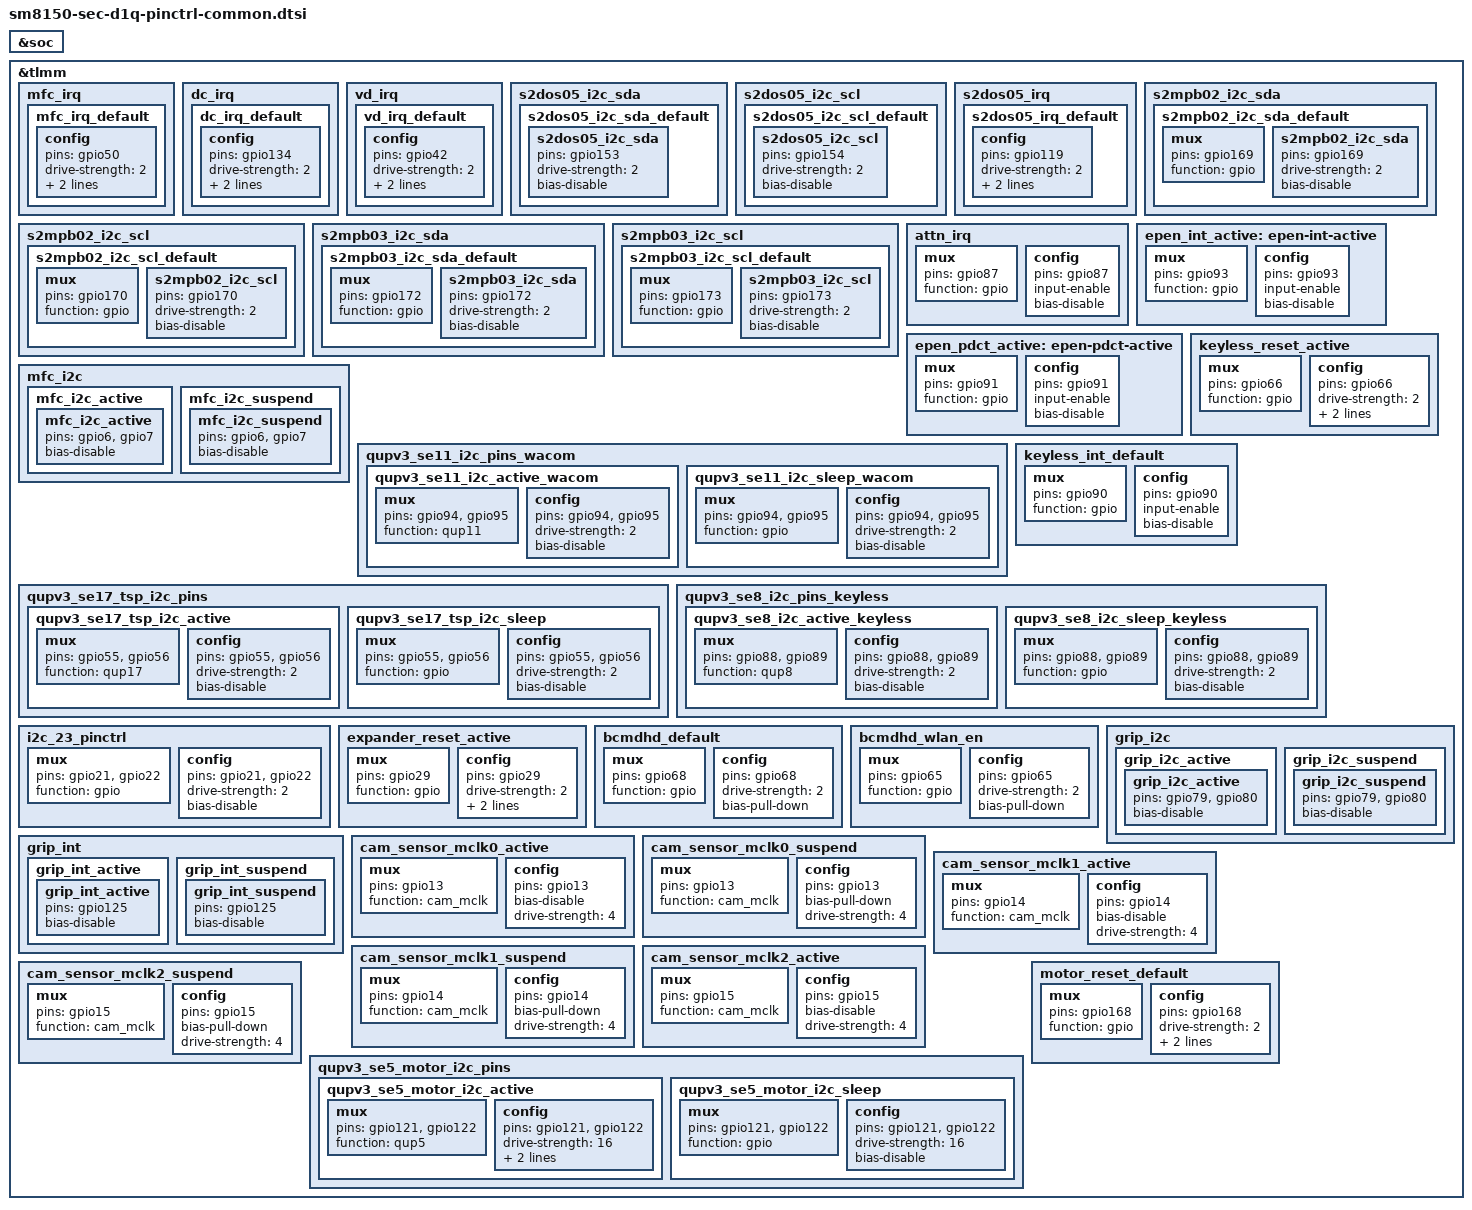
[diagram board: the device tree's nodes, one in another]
/* Copyright (c) 2016-2018, The Linux Foundation. All rights reserved.
 *
 * This program is free software; you can redistribute it and/or modify
 * it under the terms of the GNU General Public License version 2 and
 * only version 2 as published by the Free Software Foundation.
 *
 * This program is distributed in the hope that it will be useful,
 * but WITHOUT ANY WARRANTY; without even the implied warranty of
 * MERCHANTABILITY or FITNESS FOR A PARTICULAR PURPOSE.  See the
 * GNU General Public License for more details.
 */

#include "sm8150-sec-davinciq-audio-pinctrl.dtsi"

&soc {
};

&tlmm {
	mfc_irq {
		mfc_irq_default: mfc_irq_default {
			config {
				pins = "gpio50";
				drive-strength = <2>;
				bias-disable;
				input-enable;
			};
		};
	};

	dc_irq {
		dc_irq_default: dc_irq_default {
			config {
				pins = "gpio134";
				drive-strength = <2>;
				bias-disable;
				input-enable;
			};
		};
	};

	vd_irq {
		vd_irq_default: vd_irq_default {
			config {
				pins = "gpio42";
				drive-strength = <2>;
				bias-pull-up;
				input-enable;
			};
		};
	};

	s2dos05_i2c_sda {
		s2dos05_i2c_sda_default: s2dos05_i2c_sda_default {
			s2dos05_i2c_sda {
				pins = "gpio153";
				drive-strength = <2>;
				bias-disable;
			};
		};
	};
	s2dos05_i2c_scl {
		s2dos05_i2c_scl_default: s2dos05_i2c_scl_default {
			s2dos05_i2c_scl {
				pins = "gpio154";
				drive-strength = <2>;
				bias-disable;
			};
		};
	};
	s2dos05_irq {
		s2dos05_irq_default: s2dos05_irq_default {
			config {
				pins = "gpio119";
				drive-strength = <2>;
				bias-disable;
				input-enable;
			};
		};
	};

	s2mpb02_i2c_sda {
		s2mpb02_i2c_sda_default: s2mpb02_i2c_sda_default {
			mux {
				pins = "gpio169";
				function = "gpio";
			};
			s2mpb02_i2c_sda {
				pins = "gpio169";
				drive-strength = <2>;
				bias-disable;
			};
		};
	};
	s2mpb02_i2c_scl {
		s2mpb02_i2c_scl_default: s2mpb02_i2c_scl_default {
			mux {
				pins = "gpio170";
				function = "gpio";
			};
			s2mpb02_i2c_scl {
				pins = "gpio170";
				drive-strength = <2>;
				bias-disable;
			};
		};
	};

	s2mpb03_i2c_sda {
		s2mpb03_i2c_sda_default: s2mpb03_i2c_sda_default {
			mux {
				pins = "gpio172";
				function = "gpio";
			};
			s2mpb03_i2c_sda {
				pins = "gpio172";
				drive-strength = <2>;
				bias-disable;
			};
		};
	};
	s2mpb03_i2c_scl {
		s2mpb03_i2c_scl_default: s2mpb03_i2c_scl_default {
			mux {
				pins = "gpio173";
				function = "gpio";
			};
			s2mpb03_i2c_scl {
				pins = "gpio173";
				drive-strength = <2>;
				bias-disable;
			};
		};
	};

	attn_irq: attn_irq {
		mux {
			pins = "gpio87";
			function = "gpio";
		};
		config {
			pins = "gpio87";
			input-enable;
			bias-disable;
		};
	};

	epen_int_active: epen-int-active {
		mux {
			pins = "gpio93";
			function = "gpio";
		};
		config {
			pins = "gpio93";
			input-enable;
			bias-disable;
		};
	};

	epen_pdct_active: epen-pdct-active {
		mux {
			pins = "gpio91";
			function = "gpio";
		};
		config {
			pins = "gpio91";
			input-enable;
			bias-disable;
		};
	};

	mfc_i2c {
		mfc_i2c_active: mfc_i2c_active {
			mfc_i2c_active {
				pins = "gpio6", "gpio7";
				bias-disable;
			};
		};
		mfc_i2c_suspend: mfc_i2c_suspend {
			mfc_i2c_suspend {
				pins = "gpio6", "gpio7";
				bias-disable;
			};
		};
	};

	qupv3_se11_i2c_pins_wacom: qupv3_se11_i2c_pins_wacom {
		qupv3_se11_i2c_active_wacom: qupv3_se11_i2c_active_wacom {
			mux {
				pins = "gpio94", "gpio95";
				function = "qup11";
			};

			config {
				pins = "gpio94", "gpio95";
				drive-strength = <2>;
				bias-disable;
			};
		};

		qupv3_se11_i2c_sleep_wacom: qupv3_se11_i2c_sleep_wacom {
			mux {
				pins = "gpio94", "gpio95";
				function = "gpio";
			};

			config {
				pins = "gpio94", "gpio95";
				drive-strength = <2>;
				bias-disable;
			};
		};
	};

#if 0
	muic_i2c {
		muic_i2c_active: muic_i2c_active {
			muic_i2c {
				pins = "gpio25", "gpio26";
				drive-strength = <2>;
				bias-disable;
			};
		};
		muic_i2c_suspend: muic_i2c_suspend {
			muic_i2c {
				pins = "gpio25", "gpio26";
				drive-strength = <2>;
				bias-disable;
			};
		};
	};
#endif
	/* SE 17 pin mappings */
	qupv3_se17_tsp_i2c_pins: qupv3_se17_tsp_i2c_pins {
		qupv3_se17_tsp_i2c_active: qupv3_se17_tsp_i2c_active {
			mux {
				pins = "gpio55", "gpio56";
				function = "qup17";
			};

			config {
				pins = "gpio55", "gpio56";
				drive-strength = <2>;
				bias-disable;
			};
		};

		qupv3_se17_tsp_i2c_sleep: qupv3_se17_tsp_i2c_sleep {
			mux {
				pins = "gpio55", "gpio56";
				function = "gpio";
			};

			config {
				pins = "gpio55", "gpio56";
				drive-strength = <2>;
				bias-disable;
			};
		};
	};

	keyless_reset_active: keyless_reset_active {
		mux {
			pins = "gpio66";
			function = "gpio";
		};
		config {
			pins = "gpio66";
			drive-strength = <2>;   /* 16 mA */
			bias-disable;
			output-low;
		};
	};

	keyless_int_default: keyless_int_default {
		mux {
			pins = "gpio90";
			function = "gpio";
		};
		config {
			pins = "gpio90";
			input-enable;
			bias-disable;
		};
	};

	qupv3_se8_i2c_pins_keyless: qupv3_se8_i2c_pins_keyless {
		qupv3_se8_i2c_active_keyless: qupv3_se8_i2c_active_keyless {
			mux {
				pins = "gpio88", "gpio89";
				function = "qup8";
			};

			config {
				pins = "gpio88", "gpio89";
				drive-strength = <2>;
				bias-disable;
			};
		};

		qupv3_se8_i2c_sleep_keyless: qupv3_se8_i2c_sleep_keyless {
			mux {
				pins = "gpio88", "gpio89";
				function = "gpio";
			};

			config {
				pins = "gpio88", "gpio89";
				drive-strength = <2>;
				bias-disable;
			};
		};
	};

	i2c_23_pinctrl: i2c_23_pinctrl {
		mux {
			pins = "gpio21",	/* EXPANDER_I2C_SDA_1P8 */
			       "gpio22";	/* EXPANDER_I2C_SCL_1P8 */
			function = "gpio";
		};
		config {
			pins = "gpio21",	/* EXPANDER_I2C_SDA_1P8 */
			       "gpio22";	/* EXPANDER_I2C_SCL_1P8 */
			drive-strength = <2>;
			bias-disable;
		};
	};

	expander_reset_active: expander_reset_active {
		mux {
			pins = "gpio29";
			function = "gpio";
		};
		config {
			pins = "gpio29";
			drive-strength = <2>;   /* 16 mA */
			bias-disable;
			output-high;
		};
	};

	bcmdhd_default: bcmdhd_default {
		mux {
			pins = "gpio68";
			function = "gpio";
		};
		config {
			pins = "gpio68";
			drive-strength = <2>;   /* 2 mA */
			bias-pull-down;         /* PULL DOWN */
		};
	};

	bcmdhd_wlan_en: bcmdhd_wlan_en {
		mux {
			pins = "gpio65";
			function = "gpio";
		};
		config {
			pins = "gpio65";
			drive-strength = <2>;   /* 2 mA */
			bias-pull-down;         /* PULL DOWN */
		};
	};

        grip_i2c {
		grip_i2c_active: grip_i2c_active {
			grip_i2c_active {
				pins = "gpio79", "gpio80";
				bias-disable;
			};
		};
		grip_i2c_suspend: grip_i2c_suspend {
			grip_i2c_suspend {
				pins = "gpio79", "gpio80";
				bias-disable;
			};
		};
	};

	grip_int {
		grip_int_active: grip_int_active {
			grip_int_active {
				pins = "gpio125";
				bias-disable;
			};
		};
		grip_int_suspend: grip_int_suspend {
			grip_int_suspend {
				pins = "gpio125";
				bias-disable;
			};
		};
	};

	cam_sensor_mclk0_active: cam_sensor_mclk0_active {
		/* MCLK0 */
		mux {
			pins = "gpio13";
			function = "cam_mclk";
		};
		config {
			pins = "gpio13";
			bias-disable; /* No PULL */
			drive-strength = <4>; /* 4 MA */
		};
	};

	cam_sensor_mclk0_suspend: cam_sensor_mclk0_suspend {
		/* MCLK0 */
		mux {
			pins = "gpio13";
			function = "cam_mclk";
		};
		config {
			pins = "gpio13";
			bias-pull-down; /* PULL DOWN */
			drive-strength = <4>; /* 4 MA */
		};
	};

	cam_sensor_mclk1_active: cam_sensor_mclk1_active {
		/* MCLK1 */
		mux {
			pins = "gpio14";
			function = "cam_mclk";
		};
		config {
			pins = "gpio14";
			bias-disable; /* No PULL */
			drive-strength = <4>; /* 4 MA */
		};
	};

	cam_sensor_mclk1_suspend: cam_sensor_mclk1_suspend {
		/* MCLK1 */
		mux {
			pins = "gpio14";
			function = "cam_mclk";
		};
		config {
			pins = "gpio14";
			bias-pull-down; /* PULL DOWN */
			drive-strength = <4>; /* 4 MA */
		};
	};

	cam_sensor_mclk2_active: cam_sensor_mclk2_active {
		/* MCLK2 */
		mux {
			pins = "gpio15";
			function = "cam_mclk";
		};

		config {
			pins = "gpio15";
			bias-disable; /* No PULL */
			drive-strength = <4>; /* 4 MA */
		};
	};

	cam_sensor_mclk2_suspend: cam_sensor_mclk2_suspend {
		/* MCLK2 */
		mux {
			pins = "gpio15";
			function = "cam_mclk";
		};

		config {
			pins = "gpio15";
			bias-pull-down; /* PULL DOWN */
			drive-strength = <4>; /* 4 MA */
		};
	};

	/* VIB MOTOR IC */
	/delete-node/ qupv3_se5_i2c_pins;

	qupv3_se5_motor_i2c_pins: qupv3_se5_motor_i2c_pins {
		qupv3_se5_motor_i2c_active: qupv3_se5_motor_i2c_active {
			mux {
				pins = "gpio121", "gpio122";
				function = "qup5";
			};

			config {
				pins = "gpio121", "gpio122";
				drive-strength = <16>;
				output-high;
				bias-disable; /* No PULL */
			};
		};

		qupv3_se5_motor_i2c_sleep: qupv3_se5_motor_i2c_sleep {
			mux {
				pins = "gpio121", "gpio122";
				function = "gpio";
			};

			config {
				pins = "gpio121", "gpio122";
				drive-strength = <16>;
				bias-disable; /* No PULL */
			};
		};
	};

	motor_reset_default: motor_reset_default {
		mux {
			pins = "gpio168";
			function = "gpio";
		};
		config {
			pins = "gpio168";
			drive-strength = <2>;
			output-high;
			bias-pull-up;
		};
	};
};
